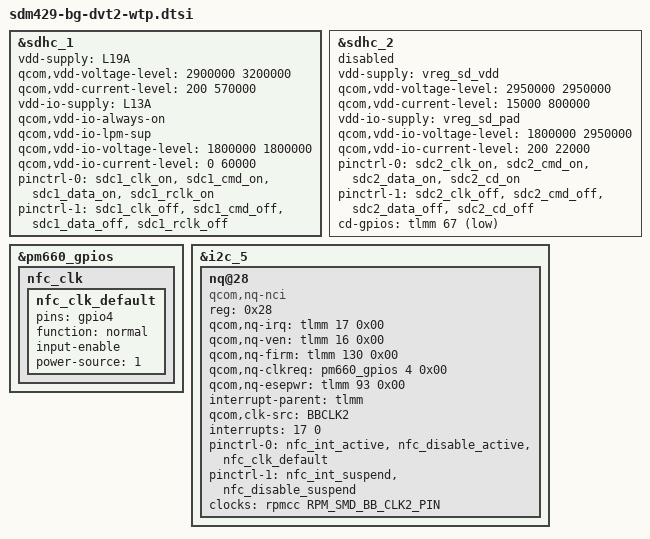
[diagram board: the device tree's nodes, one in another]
/*
 * Copyright (c) 2020, The Linux Foundation. All rights reserved.
 *
 * This program is free software; you can redistribute it and/or modify
 * it under the terms of the GNU General Public License version 2 and
 * only version 2 as published by the Free Software Foundation.
 *
 * This program is distributed in the hope that it will be useful,
 * but WITHOUT ANY WARRANTY; without even the implied warranty of
 * MERCHANTABILITY or FITNESS FOR A PARTICULAR PURPOSE.  See the
 * GNU General Public License for more details.
 */

#include "sdm429-bg-soc.dtsi"
#include "sdm429-board-common.dtsi"

&sdhc_1 {
	/* device core power supply */
	vdd-supply = <&L19A>;
	qcom,vdd-voltage-level = <2900000 3200000>;
	qcom,vdd-current-level = <200 570000>;

	/* device communication power supply */
	vdd-io-supply = <&L13A>;
	qcom,vdd-io-always-on;
	qcom,vdd-io-lpm-sup;
	qcom,vdd-io-voltage-level = <1800000 1800000>;
	qcom,vdd-io-current-level = <0 60000>;

	pinctrl-names = "active", "sleep";
	pinctrl-0 = <&sdc1_clk_on &sdc1_cmd_on &sdc1_data_on &sdc1_rclk_on>;
	pinctrl-1 = <&sdc1_clk_off &sdc1_cmd_off &sdc1_data_off &sdc1_rclk_off>;

	status = "ok";
};

&sdhc_2 {
	/* device core power supply for sd card*/
	vdd-supply = <&vreg_sd_vdd>;
	qcom,vdd-voltage-level = <2950000 2950000>;
	qcom,vdd-current-level = <15000 800000>;

	/* device communication power supply for msm_io*/
	vdd-io-supply = <&vreg_sd_pad>;
	qcom,vdd-io-voltage-level = <1800000 2950000>;
	qcom,vdd-io-current-level = <200 22000>;

	pinctrl-names = "active", "sleep";
	pinctrl-0 = <&sdc2_clk_on &sdc2_cmd_on &sdc2_data_on &sdc2_cd_on>;
	pinctrl-1 = <&sdc2_clk_off &sdc2_cmd_off &sdc2_data_off &sdc2_cd_off>;

	cd-gpios = <&tlmm 67 0x1>;

	status = "disabled";
};

&pm660_gpios {
	nfc_clk {
		nfc_clk_default: nfc_clk_default {
			pins = "gpio4";
			function = "normal";
			input-enable;
			power-source = <1>;
		};
	};
};

&i2c_5 { /* BLSP2 QUP1 (NFC) */
	#address-cells = <1>;
	#size-cells = <0>;

	status = "ok";
	nq@28 {
		compatible = "qcom,nq-nci";
		reg = <0x28>;
		qcom,nq-irq = <&tlmm 17 0x00>;
		qcom,nq-ven = <&tlmm 16 0x00>;
		qcom,nq-firm = <&tlmm 130 0x00>;
		qcom,nq-clkreq = <&pm660_gpios 4 0x00>;
		qcom,nq-esepwr = <&tlmm 93 0x00>;
		interrupt-parent = <&tlmm>;
		qcom,clk-src = "BBCLK2";
		interrupts = <17 0>;
		interrupt-names = "nfc_irq";
		pinctrl-names = "nfc_active", "nfc_suspend";
		pinctrl-0 = <&nfc_int_active &nfc_disable_active
						&nfc_clk_default>;
		pinctrl-1 = <&nfc_int_suspend &nfc_disable_suspend>;
		clocks = <&rpmcc RPM_SMD_BB_CLK2_PIN>;
		clock-names = "ref_clk";
	};
};

